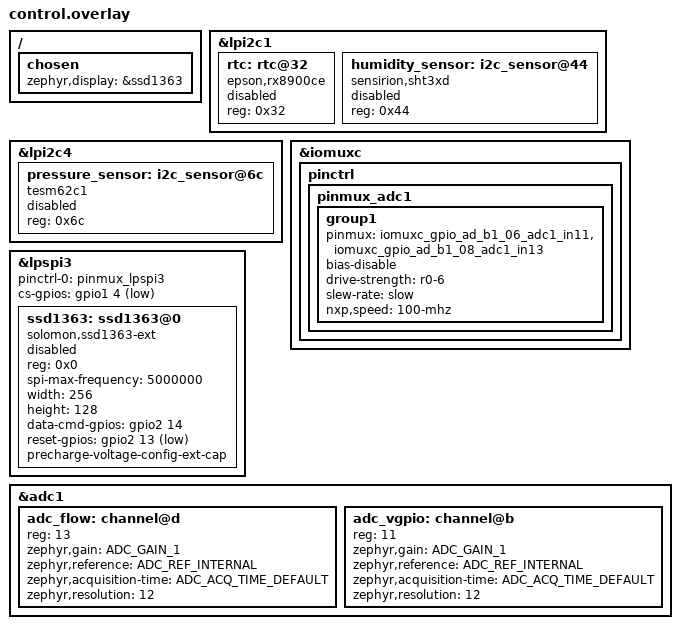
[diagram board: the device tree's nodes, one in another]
/ {
  chosen {
    zephyr,display = &ssd1363;
  };
};

//
// Extends nodes under /soc/...
// 

&lpi2c1 {
  rtc: rtc@32 {
    compatible = "epson,rx8900ce";
    status = "disabled";

    reg = <0x32>;
  };

  humidity_sensor: i2c_sensor@44 {
    compatible = "sensirion,sht3xd";
    status = "disabled";

    reg = <0x44>;
  };
};

&lpi2c4 {
  pressure_sensor: i2c_sensor@6c {
    compatible = "tesm62c1";
    status = "disabled";

    reg = <0x6c>;
  };
};

&iomuxc {
  pinctrl {
    pinmux_adc1: pinmux_adc1 {
      group1 {
        pinmux = <&iomuxc_gpio_ad_b1_06_adc1_in11>, // VGPIO (Modem)
                 <&iomuxc_gpio_ad_b1_08_adc1_in13>; // Flow
        bias-disable;
        drive-strength = "r0-6";
        slew-rate = "slow";
        nxp,speed = "100-mhz";
      };
    };
  };
};

&lpspi3 {
  pinctrl-0 = <&pinmux_lpspi3>;
  pinctrl-names = "default";

  cs-gpios = <&gpio1 4 GPIO_ACTIVE_LOW>;

  ssd1363: ssd1363@0 {
    compatible = "solomon,ssd1363-ext";
    status = "disabled";

    reg = <0x0>;

    spi-max-frequency = <5000000>;
    width = <256>;
    height = <128>;
    data-cmd-gpios = <&gpio2 14 GPIO_ACTIVE_HIGH>;
    reset-gpios = <&gpio2 13 GPIO_ACTIVE_LOW>;
    precharge-voltage-config-ext-cap;
  };
};

&adc1 {
  adc_flow: channel@d {
    reg = <13>;
    zephyr,gain = "ADC_GAIN_1";
    zephyr,reference = "ADC_REF_INTERNAL";
    zephyr,acquisition-time = <ADC_ACQ_TIME_DEFAULT>;
    zephyr,resolution = <12>;
    
    // See &pinmux_adc1 for pinctrl config
  };

  adc_vgpio: channel@b {
    reg = <11>;
    zephyr,gain = "ADC_GAIN_1";
    zephyr,reference = "ADC_REF_INTERNAL";
    zephyr,acquisition-time = <ADC_ACQ_TIME_DEFAULT>;
    zephyr,resolution = <12>;

    // See &pinmux_adc1 for pinctrl config
  };
};
